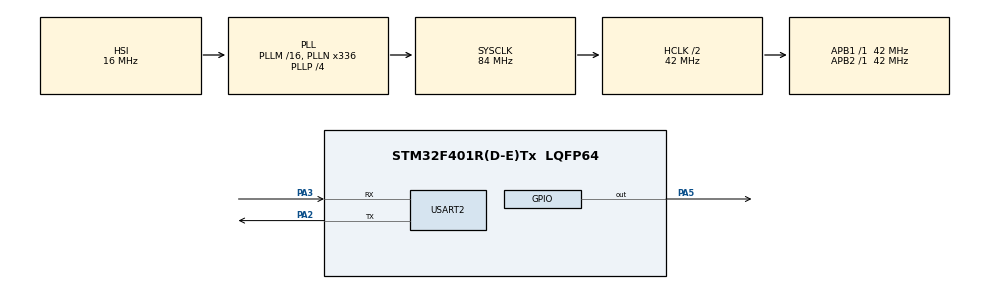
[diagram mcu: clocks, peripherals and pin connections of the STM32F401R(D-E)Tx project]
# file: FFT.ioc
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Mcu.Family=STM32F4
Mcu.Name=STM32F401R(D-E)Tx
Mcu.Package=LQFP64
NVIC.PriorityGroup=NVIC_PRIORITYGROUP_0
PA13.Mode=Serial_Wire
PA13.Signal=SYS_JTMS-SWDIO
PA14.Mode=Serial_Wire
PA14.Signal=SYS_JTCK-SWCLK
PA2.Mode=Asynchronous
PA2.Signal=USART2_TX
PA3.Mode=Asynchronous
PA3.Signal=USART2_RX
PA5.Signal=GPIO_Output
ProjectManager.HeapSize=0x200
ProjectManager.StackSize=0x400
ProjectManager.TargetToolchain=STM32CubeIDE
RCC.48MHZClocksFreq_Value=48000000
RCC.AHBCLKDivider=RCC_SYSCLK_DIV2
RCC.AHBFreq_Value=42000000
RCC.APB1Freq_Value=42000000
RCC.APB1TimFreq_Value=42000000
RCC.APB2Freq_Value=42000000
RCC.APB2TimFreq_Value=42000000
RCC.CortexFreq_Value=42000000
RCC.HCLKFreq_Value=42000000
RCC.HSE_VALUE=8000000
RCC.HSI_VALUE=16000000
RCC.LSE_VALUE=32768
RCC.PLLN=336
RCC.PLLP=RCC_PLLP_DIV4
RCC.PLLQ=7
RCC.SYSCLKFreq_VALUE=84000000
RCC.SYSCLKSource=RCC_SYSCLKSOURCE_PLLCLK
RCC.VCOOutputFreq_Value=336000000
USART2.VirtualMode=VM_ASYNC
board=NUCLEO-F401RE

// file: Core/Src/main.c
/* USER CODE BEGIN Header */
/**
  ******************************************************************************
  * @file           : main.c
  * @brief          : Main program body
  ******************************************************************************
  * @attention
  *
  * Copyright (c) 2023 STMicroelectronics.
  * All rights reserved.
  *
  * This software is licensed under terms that can be found in the LICENSE file
  * in the root directory of this software component.
  * If no LICENSE file comes with this software, it is provided AS-IS.
  *
  ******************************************************************************
  */
/* USER CODE END Header */
#include "main.h"

/* USER CODE BEGIN Includes */
#include <string.h>
#include <stdio.h>
#define ARM_MATH_CM4
#include "arm_math.h"

/* USER CODE END Includes */

/* USER CODE BEGIN PD */
#define FFT_BUFFER_SIZE 4096
#define SAMPLING_RATE 16000
arm_rfft_fast_instance_f32 fftHandler;
float32_t fftBuffIn[FFT_BUFFER_SIZE];
float32_t fftBuffOut[FFT_BUFFER_SIZE];
float32_t outputfft_mag[FFT_BUFFER_SIZE/2];
uint8_t fftFlag=0;
float32_t frequency1 = 5000;
float32_t frequency2 = 500;

/*

uint32_t adcVal[2];
uint32_t X_axis;
double Y_axis;
double reference_voltage = 3.3;
int adc_resolution = 4095;
double bias_offset = 1.65;
double sensitivity = 0.3;
*/
/* USER CODE END PD */

UART_HandleTypeDef huart2;

void SystemClock_Config(void);
static void MX_GPIO_Init(void);
static void MX_USART2_UART_Init(void);

int main(void)
{
  /* USER CODE BEGIN 1 */
	arm_rfft_fast_init_f32(&fftHandler, FFT_BUFFER_SIZE);
  /* USER CODE END 1 */

  /* MCU Configuration--------------------------------------------------------*/

  /* Reset of all peripherals, Initializes the Flash interface and the Systick. */
  HAL_Init();

  /* Configure the system clock */
  SystemClock_Config();

  /* Initialize all configured peripherals */
  MX_GPIO_Init();
  MX_USART2_UART_Init();
  /* USER CODE BEGIN 2 */
 // HAL_TIM_Base_Start(&htim2);
  //Start ADC after timer
  //HAL_ADC_Start_DMA(&hadc1,adcVal,2);
  HAL_Delay(100);
  	  for(int i = 0; i<FFT_BUFFER_SIZE; i++){
	   fftBuffIn[i]= arm_sin_f32(2 * PI * i * frequency1 /SAMPLING_RATE) + arm_sin_f32(2 * PI * i * frequency2 /SAMPLING_RATE);
  	  	  }
 			arm_rfft_fast_f32(&fftHandler,fftBuffIn,fftBuffOut,0); // 0 means we are applying Fourier transform, 1 means inverse
 			arm_cmplx_mag_f32(fftBuffOut, outputfft_mag, FFT_BUFFER_SIZE/2);
        	for (int i = 0;  i< FFT_BUFFER_SIZE/2; i++)
 		  {
        	char buffer[100];
        	snprintf(buffer, sizeof(buffer),"frequency %f: %f\r\n", ((float32_t)(i * SAMPLING_RATE)/ FFT_BUFFER_SIZE),outputfft_mag[i]);
        	HAL_UART_Transmit(&huart2, (uint8_t *)buffer, strlen(buffer), HAL_MAX_DELAY);
 		  }

  /* USER CODE END 2 */

  /* Infinite loop */
  while (1)
  {

  }
}

void SystemClock_Config(void)
{
  RCC_OscInitTypeDef RCC_OscInitStruct = {0};
  RCC_ClkInitTypeDef RCC_ClkInitStruct = {0};

  /** Configure the main internal regulator output voltage
  */
  __HAL_RCC_PWR_CLK_ENABLE();
  __HAL_PWR_VOLTAGESCALING_CONFIG(PWR_REGULATOR_VOLTAGE_SCALE2);

  /** Initializes the RCC Oscillators according to the specified parameters
  * in the RCC_OscInitTypeDef structure.
  */
  RCC_OscInitStruct.OscillatorType = RCC_OSCILLATORTYPE_HSI;
  RCC_OscInitStruct.HSIState = RCC_HSI_ON;
  RCC_OscInitStruct.HSICalibrationValue = RCC_HSICALIBRATION_DEFAULT;
  RCC_OscInitStruct.PLL.PLLState = RCC_PLL_ON;
  RCC_OscInitStruct.PLL.PLLSource = RCC_PLLSOURCE_HSI;
  RCC_OscInitStruct.PLL.PLLM = 16;
  RCC_OscInitStruct.PLL.PLLN = 336;
  RCC_OscInitStruct.PLL.PLLP = RCC_PLLP_DIV4;
  RCC_OscInitStruct.PLL.PLLQ = 7;
  if (HAL_RCC_OscConfig(&RCC_OscInitStruct) != HAL_OK)
  {
    Error_Handler();
  }

  /** Initializes the CPU, AHB and APB buses clocks
  */
  RCC_ClkInitStruct.ClockType = RCC_CLOCKTYPE_HCLK|RCC_CLOCKTYPE_SYSCLK
                              |RCC_CLOCKTYPE_PCLK1|RCC_CLOCKTYPE_PCLK2;
  RCC_ClkInitStruct.SYSCLKSource = RCC_SYSCLKSOURCE_PLLCLK;
  RCC_ClkInitStruct.AHBCLKDivider = RCC_SYSCLK_DIV2;
  RCC_ClkInitStruct.APB1CLKDivider = RCC_HCLK_DIV1;
  RCC_ClkInitStruct.APB2CLKDivider = RCC_HCLK_DIV1;

  if (HAL_RCC_ClockConfig(&RCC_ClkInitStruct, FLASH_LATENCY_1) != HAL_OK)
  {
    Error_Handler();
  }
}

static void MX_USART2_UART_Init(void)
{

  huart2.Instance = USART2;
  huart2.Init.BaudRate = 115200;
  huart2.Init.WordLength = UART_WORDLENGTH_8B;
  huart2.Init.StopBits = UART_STOPBITS_1;
  huart2.Init.Parity = UART_PARITY_NONE;
  huart2.Init.Mode = UART_MODE_TX_RX;
  huart2.Init.HwFlowCtl = UART_HWCONTROL_NONE;
  huart2.Init.OverSampling = UART_OVERSAMPLING_16;
  if (HAL_UART_Init(&huart2) != HAL_OK)
  {
    Error_Handler();
  }

}

static void MX_GPIO_Init(void)
{
  GPIO_InitTypeDef GPIO_InitStruct = {0};

  /* GPIO Ports Clock Enable */
  __HAL_RCC_GPIOA_CLK_ENABLE();

  /*Configure GPIO pin Output Level */
  HAL_GPIO_WritePin(GPIOA, GPIO_PIN_5, GPIO_PIN_RESET);

  /*Configure GPIO pin : PA5 */
  GPIO_InitStruct.Pin = GPIO_PIN_5;
  GPIO_InitStruct.Mode = GPIO_MODE_OUTPUT_PP;
  GPIO_InitStruct.Pull = GPIO_NOPULL;
  GPIO_InitStruct.Speed = GPIO_SPEED_FREQ_LOW;
  HAL_GPIO_Init(GPIOA, &GPIO_InitStruct);

}

/* USER CODE BEGIN 4 */
/*
void HAL_ADC_ConvCpltCallback(ADC_HandleTypeDef* hadc)
{
	UNUSED(hadc1);
	HAL_GPIO_TogglePin(GPIOA, GPIO_PIN_5);
}
*/

int _write(int file, char *ptr, int len)
{
  (void)file;
  int DataIdx;

  for (DataIdx = 0; DataIdx < len; DataIdx++)
  {
    ITM_SendChar(*ptr++);
  }
  return len;
}

/* USER CODE END 4 */

void Error_Handler(void)
{
  __disable_irq();
  while (1)
  {
  }
}
